# MKM33Z5 register map
File version: 1.6
Registers are 8-bit, read-write, reset 0x0 unless marked. A register's access mark holds for its fields unless they carry their own. Offsets are from the block's base; [hi:lo] are bit positions; {n}, {i} and the like mark numbered series.

## WDOG — Generation 2008 Watchdog Timer
Base 0x40053000; register names take the prefix WDOG_
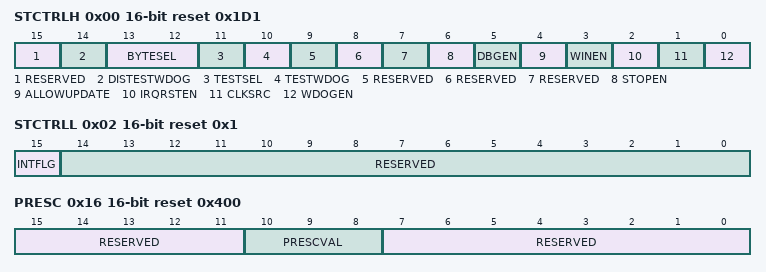
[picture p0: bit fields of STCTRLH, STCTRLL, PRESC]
0x00 STCTRLH 16-bit reset 0x1D1 — Watchdog Status and Control Register High
  [15] RESERVED ro
  [14] DISTESTWDOG
    0=WDOG functional test mode is not disabled; 1=WDOG functional test mode is disabled permanently until reset
  [13:12] BYTESEL
    {v}=Byte {v} selected (v=0..3)
  [11] TESTSEL
    0=Quick test. The timer runs in normal operation. You can load a small time-out value to do a quick test.; 1=Byte test. Puts the timer in the byte test mode where individual bytes of the timer are enabled for operation and are compared for time-out against the corresponding byte of the programmed time-out value. Select the byte through BYTESEL[1:0] for testing.
  [10] TESTWDOG
  [9] RESERVED ro
  [8] RESERVED
  [7] RESERVED ro
  [6] STOPEN
    0=WDOG is disabled in CPU Stop mode; 1=WDOG is enabled in CPU Stop mode
  [5] DBGEN
    0=WDOG is disabled in CPU Debug mode; 1=WDOG is enabled in CPU Debug mode
  [4] ALLOWUPDATE
    0=No further updates allowed to WDOG write-once registers; 1=WDOG write-once registers can be unlocked for updating
  [3] WINEN
    0=Windowing mode is disabled; 1=Windowing mode is enabled
  [2] IRQRSTEN
    0=WDOG time-out generates reset only; 1=WDOG time-out initially generates an interrupt. After WCT, it generates a reset.
  [1] CLKSRC
    0=WDOG clock sourced from LPO ; 1=WDOG clock sourced from alternate clock source
  [0] WDOGEN
    0=WDOG is disabled; 1=WDOG is enabled
0x02 STCTRLL 16-bit reset 0x1 — Watchdog Status and Control Register Low
  [15] INTFLG, [14:0] RESERVED
0x04 TOVALH 16-bit reset 0x4C — Watchdog Time-out Value Register High
  [15:0] TOVALHIGH
0x06 TOVALL 16-bit reset 0x4B40 — Watchdog Time-out Value Register Low
  [15:0] TOVALLOW
0x08 WINH 16-bit — Watchdog Window Register High
  [15:0] WINHIGH
0x0A WINL 16-bit reset 0x10 — Watchdog Window Register Low
  [15:0] WINLOW
0x0C REFRESH 16-bit reset 0xB480 — Watchdog Refresh register
  [15:0] WDOGREFRESH
0x0E UNLOCK 16-bit reset 0xD928 — Watchdog Unlock register
  [15:0] WDOGUNLOCK
0x10 TMROUTH 16-bit — Watchdog Timer Output Register High
  [15:0] TIMEROUTHIGH
0x12 TMROUTL 16-bit — Watchdog Timer Output Register Low
  [15:0] TIMEROUTLOW
0x14 RSTCNT 16-bit — Watchdog Reset Count register
0x16 PRESC 16-bit reset 0x400 — Watchdog Prescaler register
  [15:11] RESERVED ro, [10:8] PRESCVAL, [7:0] RESERVED ro

## XBAR — Crossbar Switch
Base 0x40055000; register names take the prefix XBAR_
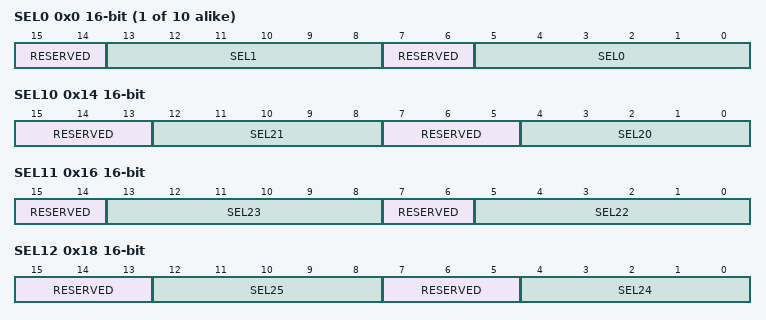
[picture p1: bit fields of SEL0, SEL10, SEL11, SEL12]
{0x0+2i} SEL{i} 16-bit (i=0..9) — Crossbar Select Register {i}
  [15:14] RESERVED ro, [13:8] SEL{2i+1}, [7:6] RESERVED ro, [5:0] SEL{2i}
0x14 SEL10 16-bit — Crossbar Select Register 10
  [15:13] RESERVED ro, [12:8] SEL21, [7:5] RESERVED ro, [4:0] SEL20
0x16 SEL11 16-bit — Crossbar Select Register 11
  [15:14] RESERVED ro, [13:8] SEL23, [7:6] RESERVED ro, [5:0] SEL22
0x18 SEL12 16-bit — Crossbar Select Register 12
  [15:13] RESERVED ro, [12:8] SEL25, [7:5] RESERVED ro, [4:0] SEL24
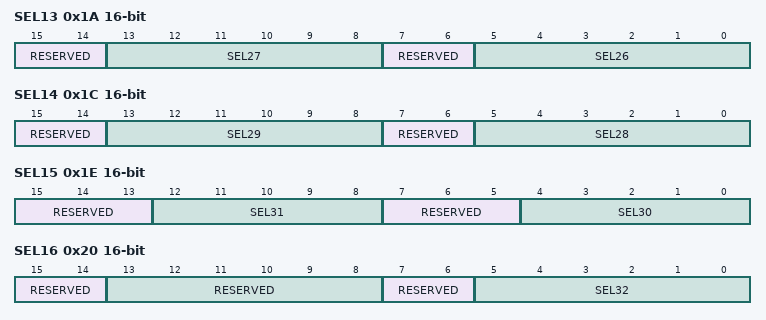
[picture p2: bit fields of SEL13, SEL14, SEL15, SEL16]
0x1A SEL13 16-bit — Crossbar Select Register 13
  [15:14] RESERVED ro, [13:8] SEL27, [7:6] RESERVED ro, [5:0] SEL26
0x1C SEL14 16-bit — Crossbar Select Register 14
  [15:14] RESERVED ro, [13:8] SEL29, [7:6] RESERVED ro, [5:0] SEL28
0x1E SEL15 16-bit — Crossbar Select Register 15
  [15:13] RESERVED ro, [12:8] SEL31, [7:5] RESERVED ro, [4:0] SEL30
0x20 SEL16 16-bit — Crossbar Select Register 16
  [15:14] RESERVED ro, [13:8] RESERVED ro, [7:6] RESERVED ro, [5:0] SEL32
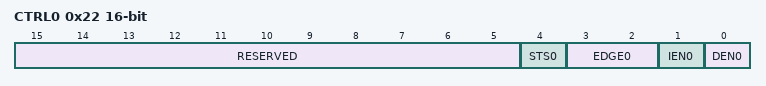
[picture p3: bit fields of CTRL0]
0x22 CTRL0 16-bit — Crossbar Control Register 0
  [15:5] RESERVED ro
  [4] STS0 — Edge detection status for XBAR_OUT0
    0=Active edge not yet detected on XBAR_OUT0; 1=Active edge detected on XBAR_OUT0
  [3:2] EDGE0 — Active edge for edge detection on XBAR_OUT0
    0=STS0 never asserts; 1=STS0 asserts on rising edges of XBAR_OUT0; 2=STS0 asserts on falling edges of XBAR_OUT0; 3=STS0 asserts on rising and falling edges of XBAR_OUT0
  [1] IEN0 — Interrupt Enable for XBAR_OUT0
    0=Interrupt disabled; 1=Interrupt enabled
  [0] DEN0 — DMA Enable for XBAR_OUT0
    0=DMA disabled; 1=DMA enabled
